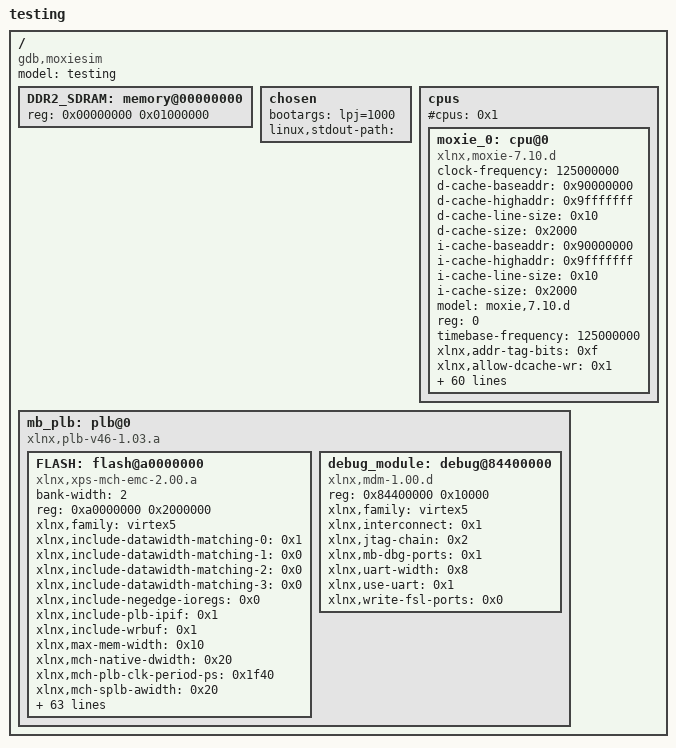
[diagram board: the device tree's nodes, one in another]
/*
 * GDB Simulator device tree.
 *
 * (C) Copyright 2009 Anthony Green
 *
 * Anthony Green <green@moxielogic.com>
 *
 * This program is free software; you can redistribute it and/or
 * modify it under the terms of the GNU General Public License as
 * published by the Free Software Foundation; either version 2 of
 * the License, or (at your option) any later version.
 *
 * This program is distributed in the hope that it will be useful,
 * but WITHOUT ANY WARRANTY; without even the implied warranty of
 * MERCHANTABILITY or FITNESS FOR A PARTICULAR PURPOSE. See the
 * GNU General Public License for more details.
 *
 * You should have received a copy of the GNU General Public License
 * along with this program; if not, write to the Free Software
 * Foundation, Inc., 59 Temple Place, Suite 330, Boston,
 * MA 02111-1307 USA
 *
 */

/dts-v1/;
/ {
	#address-cells = <1>;
	#size-cells = <1>;
	compatible = "gdb,moxiesim";
	model = "testing";
	DDR2_SDRAM: memory@00000000 {
		device_type = "memory";
		reg = < 0x00000000 0x01000000 >;
	} ;
	chosen {
		bootargs = "lpj=1000";
		linux,stdout-path = "";
	} ;
	cpus {
		#address-cells = <1>;
		#cpus = <0x1>;
		#size-cells = <0>;
		moxie_0: cpu@0 {
			clock-frequency = <125000000>;
			compatible = "xlnx,moxie-7.10.d";
			d-cache-baseaddr = <0x90000000>;
			d-cache-highaddr = <0x9fffffff>;
			d-cache-line-size = <0x10>;
			d-cache-size = <0x2000>;
			device_type = "cpu";
			i-cache-baseaddr = <0x90000000>;
			i-cache-highaddr = <0x9fffffff>;
			i-cache-line-size = <0x10>;
			i-cache-size = <0x2000>;
			model = "moxie,7.10.d";
			reg = <0>;
			timebase-frequency = <125000000>;
			xlnx,addr-tag-bits = <0xf>;
			xlnx,allow-dcache-wr = <0x1>;
			xlnx,allow-icache-wr = <0x1>;
			xlnx,area-optimized = <0x0>;
			xlnx,cache-byte-size = <0x2000>;
			xlnx,d-lmb = <0x1>;
			xlnx,d-opb = <0x0>;
			xlnx,d-plb = <0x1>;
			xlnx,data-size = <0x20>;
			xlnx,dcache-addr-tag = <0xf>;
			xlnx,dcache-always-used = <0x1>;
			xlnx,dcache-byte-size = <0x2000>;
			xlnx,dcache-line-len = <0x4>;
			xlnx,dcache-use-fsl = <0x1>;
			xlnx,debug-enabled = <0x1>;
			xlnx,div-zero-exception = <0x1>;
			xlnx,dopb-bus-exception = <0x0>;
			xlnx,dynamic-bus-sizing = <0x1>;
			xlnx,edge-is-positive = <0x1>;
			xlnx,family = "virtex5";
			xlnx,fpu-exception = <0x1>;
			xlnx,fsl-data-size = <0x20>;
			xlnx,fsl-exception = <0x0>;
			xlnx,fsl-links = <0x0>;
			xlnx,i-lmb = <0x1>;
			xlnx,i-opb = <0x0>;
			xlnx,i-plb = <0x1>;
			xlnx,icache-always-used = <0x1>;
			xlnx,icache-line-len = <0x4>;
			xlnx,icache-use-fsl = <0x1>;
			xlnx,ill-opcode-exception = <0x1>;
			xlnx,instance = "moxie_0";
			xlnx,interconnect = <0x1>;
			xlnx,interrupt-is-edge = <0x0>;
			xlnx,iopb-bus-exception = <0x0>;
			xlnx,mmu-dtlb-size = <0x4>;
			xlnx,mmu-itlb-size = <0x2>;
			xlnx,mmu-tlb-access = <0x3>;
			xlnx,mmu-zones = <0x10>;
			xlnx,number-of-pc-brk = <0x1>;
			xlnx,number-of-rd-addr-brk = <0x0>;
			xlnx,number-of-wr-addr-brk = <0x0>;
			xlnx,opcode-0x0-illegal = <0x1>;
			xlnx,pvr = <0x2>;
			xlnx,pvr-user1 = <0x0>;
			xlnx,pvr-user2 = <0x0>;
			xlnx,reset-msr = <0x0>;
			xlnx,sco = <0x0>;
			xlnx,unaligned-exceptions = <0x1>;
			xlnx,use-barrel = <0x1>;
			xlnx,use-dcache = <0x1>;
			xlnx,use-div = <0x1>;
			xlnx,use-ext-brk = <0x1>;
			xlnx,use-ext-nm-brk = <0x1>;
			xlnx,use-extended-fsl-instr = <0x0>;
			xlnx,use-fpu = <0x2>;
			xlnx,use-hw-mul = <0x2>;
			xlnx,use-icache = <0x1>;
			xlnx,use-interrupt = <0x1>;
			xlnx,use-mmu = <0x3>;
			xlnx,use-msr-instr = <0x1>;
			xlnx,use-pcmp-instr = <0x1>;
		} ;
	} ;
	mb_plb: plb@0 {
		#address-cells = <1>;
		#size-cells = <1>;
		compatible = "xlnx,plb-v46-1.03.a", "simple-bus";
		ranges ;
		FLASH: flash@a0000000 {
			bank-width = <2>;
			compatible = "xlnx,xps-mch-emc-2.00.a", "cfi-flash";
			reg = < 0xa0000000 0x2000000 >;
			xlnx,family = "virtex5";
			xlnx,include-datawidth-matching-0 = <0x1>;
			xlnx,include-datawidth-matching-1 = <0x0>;
			xlnx,include-datawidth-matching-2 = <0x0>;
			xlnx,include-datawidth-matching-3 = <0x0>;
			xlnx,include-negedge-ioregs = <0x0>;
			xlnx,include-plb-ipif = <0x1>;
			xlnx,include-wrbuf = <0x1>;
			xlnx,max-mem-width = <0x10>;
			xlnx,mch-native-dwidth = <0x20>;
			xlnx,mch-plb-clk-period-ps = <0x1f40>;
			xlnx,mch-splb-awidth = <0x20>;
			xlnx,mch0-accessbuf-depth = <0x10>;
			xlnx,mch0-protocol = <0x0>;
			xlnx,mch0-rddatabuf-depth = <0x10>;
			xlnx,mch1-accessbuf-depth = <0x10>;
			xlnx,mch1-protocol = <0x0>;
			xlnx,mch1-rddatabuf-depth = <0x10>;
			xlnx,mch2-accessbuf-depth = <0x10>;
			xlnx,mch2-protocol = <0x0>;
			xlnx,mch2-rddatabuf-depth = <0x10>;
			xlnx,mch3-accessbuf-depth = <0x10>;
			xlnx,mch3-protocol = <0x0>;
			xlnx,mch3-rddatabuf-depth = <0x10>;
			xlnx,mem0-width = <0x10>;
			xlnx,mem1-width = <0x20>;
			xlnx,mem2-width = <0x20>;
			xlnx,mem3-width = <0x20>;
			xlnx,num-banks-mem = <0x1>;
			xlnx,num-channels = <0x0>;
			xlnx,priority-mode = <0x0>;
			xlnx,synch-mem-0 = <0x0>;
			xlnx,synch-mem-1 = <0x0>;
			xlnx,synch-mem-2 = <0x0>;
			xlnx,synch-mem-3 = <0x0>;
			xlnx,synch-pipedelay-0 = <0x2>;
			xlnx,synch-pipedelay-1 = <0x2>;
			xlnx,synch-pipedelay-2 = <0x2>;
			xlnx,synch-pipedelay-3 = <0x2>;
			xlnx,tavdv-ps-mem-0 = <0x1adb0>;
			xlnx,tavdv-ps-mem-1 = <0x3a98>;
			xlnx,tavdv-ps-mem-2 = <0x3a98>;
			xlnx,tavdv-ps-mem-3 = <0x3a98>;
			xlnx,tcedv-ps-mem-0 = <0x1adb0>;
			xlnx,tcedv-ps-mem-1 = <0x3a98>;
			xlnx,tcedv-ps-mem-2 = <0x3a98>;
			xlnx,tcedv-ps-mem-3 = <0x3a98>;
			xlnx,thzce-ps-mem-0 = <0x88b8>;
			xlnx,thzce-ps-mem-1 = <0x1b58>;
			xlnx,thzce-ps-mem-2 = <0x1b58>;
			xlnx,thzce-ps-mem-3 = <0x1b58>;
			xlnx,thzoe-ps-mem-0 = <0x1b58>;
			xlnx,thzoe-ps-mem-1 = <0x1b58>;
			xlnx,thzoe-ps-mem-2 = <0x1b58>;
			xlnx,thzoe-ps-mem-3 = <0x1b58>;
			xlnx,tlzwe-ps-mem-0 = <0x88b8>;
			xlnx,tlzwe-ps-mem-1 = <0x0>;
			xlnx,tlzwe-ps-mem-2 = <0x0>;
			xlnx,tlzwe-ps-mem-3 = <0x0>;
			xlnx,twc-ps-mem-0 = <0x2af8>;
			xlnx,twc-ps-mem-1 = <0x3a98>;
			xlnx,twc-ps-mem-2 = <0x3a98>;
			xlnx,twc-ps-mem-3 = <0x3a98>;
			xlnx,twp-ps-mem-0 = <0x11170>;
			xlnx,twp-ps-mem-1 = <0x2ee0>;
			xlnx,twp-ps-mem-2 = <0x2ee0>;
			xlnx,twp-ps-mem-3 = <0x2ee0>;
			xlnx,xcl0-linesize = <0x4>;
			xlnx,xcl0-writexfer = <0x1>;
			xlnx,xcl1-linesize = <0x4>;
			xlnx,xcl1-writexfer = <0x1>;
			xlnx,xcl2-linesize = <0x4>;
			xlnx,xcl2-writexfer = <0x1>;
			xlnx,xcl3-linesize = <0x4>;
			xlnx,xcl3-writexfer = <0x1>;
		} ;
		debug_module: debug@84400000 {
			compatible = "xlnx,mdm-1.00.d";
			reg = < 0x84400000 0x10000 >;
			xlnx,family = "virtex5";
			xlnx,interconnect = <0x1>;
			xlnx,jtag-chain = <0x2>;
			xlnx,mb-dbg-ports = <0x1>;
			xlnx,uart-width = <0x8>;
			xlnx,use-uart = <0x1>;
			xlnx,write-fsl-ports = <0x0>;
		} ;
	} ;
}  ;
